# A31G12x register map
Vendor: VENDOR ABOV Semiconductor Co., Ltd.; Series: A31G12x; File version: 1.0
CPU: CM0+ r0p1, little endian, no MPU, no FPU, VTOR, 2 interrupt priority bits
Registers are 32-bit, read-write, reset 0x0 unless marked. A register's access mark holds for its fields unless they carry their own. Offsets are from the block's base; [hi:lo] are bit positions.

## UARTn
Base 0x55000000
Same registers: UART0 0x40004000, UART1 0x40004100
0x00 RBR ro — UARTn Receive Data Buffer Register
  [7:0] RBR — UARTn Receive Data Buffer
0x00 THR wo — UARTn Transmit Data Hold Register
  [7:0] THR — UARTn Transmit Data Hold
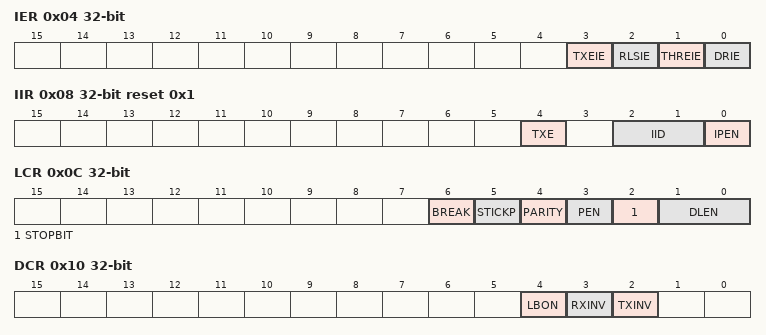
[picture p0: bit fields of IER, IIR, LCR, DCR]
0x04 IER — UARTn Interrupt Enable Register
  [3] TXEIE — Transmit Empty Interrupt Enable
  [2] RLSIE — Receiver Line Status Interrupt Enable
  [1] THREIE — Transmit Holding Register Empty Interrupt Enable
  [0] DRIE — Data Receive Interrupt Enable
0x08 IIR ro reset 0x1 — UARTn Interrupt ID Register
  [4] TXE — Transmit Complete Interrupt Source ID
  [2:1] IID — UARTn Interrupt ID
  [0] IPEN — Interrupt Pending
0x0C LCR — UARTn Line Control Register
  [6] BREAK — Transfer Break Control
  [5] STICKP — Force Parity
  [4] PARITY — Parity Mode and Parity Stuck Selection
  [3] PEN — Parity Bit Transfer Enable
  [2] STOPBIT — Stop Bit Length Selection
  [1:0] DLEN — Data Length Selection
0x10 DCR — UARTn Data Control Register
  [4] LBON — Local Loopback Test Mode Enable
  [3] RXINV — Receive Data Inversion Selection
  [2] TXINV — Transmit Data Inversion Selection
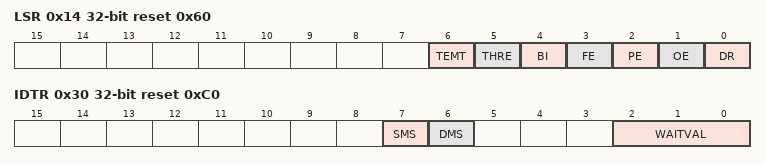
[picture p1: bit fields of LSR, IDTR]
0x14 LSR ro reset 0x60 — UARTn Line Status Register
  [6] TEMT — Transmit Register Empty
  [5] THRE — Transmit Hold Register Empty
  [4] BI — Break Condition Indication
  [3] FE — Frame Error Indicator
  [2] PE — Parity Error Indicator
  [1] OE — Overrun Error Indicator
  [0] DR — Data Receive Indicator
0x20 BDR — UARTn Baud Rate Divisor Latch Register
  [15:0] BDR — Baud Rate Divider Latch Value
0x24 BFR — UARTn Baud Rate Fractional Counter Value
  [7:0] BFR — Fraction Counter value
    0=Disable fraction counter
0x30 IDTR reset 0xC0 — UARTn Inter-frame Delay Time Register
  [7] SMS — Start Bit Multi Sampling Enable
  [6] DMS — Data Bit Multi Sampling Enable
  [2:0] WAITVAL — Wait Time Value

## I2Cn
Base 0x56000000
Same registers: I2C0 0x40004800, I2C1 0x40004900, I2C2 0x40004A00
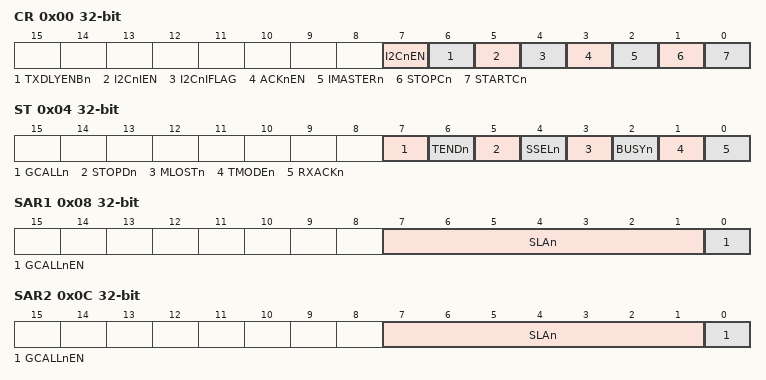
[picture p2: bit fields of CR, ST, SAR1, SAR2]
0x00 CR — I2Cn Control Register
  [7] I2CnEN — Activate I2Cn Block by supplying
  [6] TXDLYENBn — SDHR Register Control
  [5] I2CnIEN — I2Cn Interrupt Enable
  [4] I2CnIFLAG — I2Cn Interrupt Flag
  [3] ACKnEN — Controls ACK signal generation at ninth SCL period
  [2] IMASTERn ro — Represent Operation Mode of I2Cn
  [1] STOPCn — STOP Condition Generation when I2Cn is master
  [0] STARTCn — START Condition Generation when I2Cn is master
0x04 ST — I2Cn Status Register
  [7] GCALLn — This bit has different meaning depending on whether I2C is master or slave. When I2C is a master, this bit represents whether it received AACK (address ACK) from slave. When I2C is a slave, this bit is used to indicate general call.
  [6] TENDn — This bit is set when 1-byte of data is transferred completely
  [5] STOPDn — This bit is set when a STOP condition is detected
  [4] SSELn — This bit is set when I2C is addressed by other master
  [3] MLOSTn — This bit represents the result of bus arbitration in master mode
  [2] BUSYn — This bit reflects bus status
  [1] TMODEn ro — This bit is used to indicate whether I2C is transmitter or receiver
  [0] RXACKn — This bit shows the state of ACK signal
0x08 SAR1 — I2Cn Slave Address Register 1
  [7:1] SLAn — These bits configure the slave address 1 in slave mode
  [0] GCALLnEN — This bit decides whether I2Cn allows general call address 1 or not in I2Cn slave mode
0x0C SAR2 — I2Cn Slave Address Register 2
  [7:1] SLAn — These bits configure the slave address 2 in slave mode
  [0] GCALLnEN — This bit decides whether I2Cn allows general call address 2 or not in I2Cn slave mode
0x10 DR — I2Cn Data Register
  [7:0] DATA — The DR Transmit buffer and Receive buffer share the same I/O address with this DATA register
0x14 SDHR reset 0x1 — I2Cn SDA Hold Time Register
  [11:0] HLDT — This register is used to control SDA output timing from the falling edge of SCL
0x18 SCLR reset 0x3F — I2Cn SCL Low Period Register
  [11:0] SCLL — This register defines the low period of SCL in master mode
0x1C SCHR reset 0x3F — I2Cn SCL High Period Register
  [11:0] SCLH — This register defines the high period of SCL in master mode
